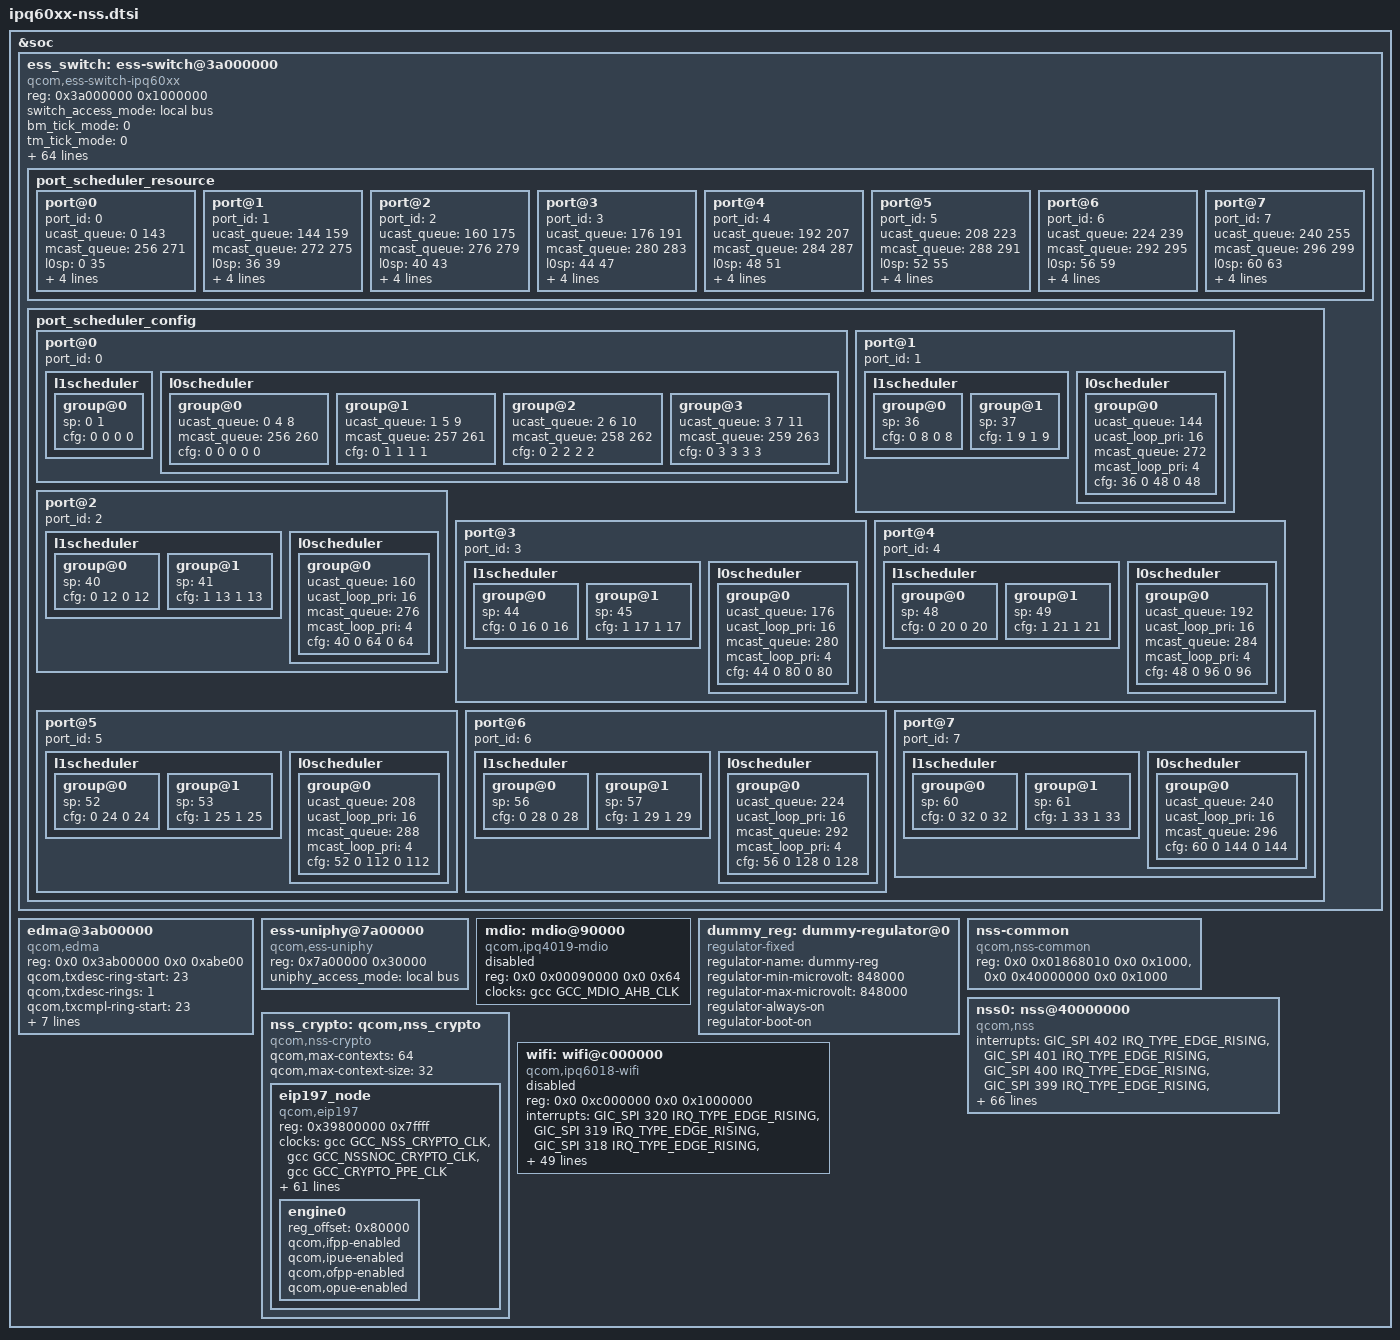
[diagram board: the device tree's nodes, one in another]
// SPDX-License-Identifier: GPL-2.0-only

&soc {
	ess_switch: ess-switch@3a000000 {
		compatible = "qcom,ess-switch-ipq60xx";
		reg = <0x3a000000 0x1000000>;
		switch_access_mode = "local bus";
    		bm_tick_mode = <0>; /* bm tick mode */
    		tm_tick_mode = <0>; /* tm tick mode */
		mdio-bus = <&mdio>;
		clocks = <&gcc GCC_CMN_12GPLL_AHB_CLK>,
			<&gcc GCC_CMN_12GPLL_SYS_CLK>,
			<&gcc GCC_UNIPHY0_AHB_CLK>,
			<&gcc GCC_UNIPHY0_SYS_CLK>,
			<&gcc GCC_UNIPHY1_AHB_CLK>,
			<&gcc GCC_UNIPHY1_SYS_CLK>,
			<&gcc GCC_PORT1_MAC_CLK>,
			<&gcc GCC_PORT2_MAC_CLK>,
			<&gcc GCC_PORT3_MAC_CLK>,
			<&gcc GCC_PORT4_MAC_CLK>,
			<&gcc GCC_PORT5_MAC_CLK>,
			<&gcc GCC_NSS_PPE_CLK>,
			<&gcc GCC_NSS_PPE_CFG_CLK>,
			<&gcc GCC_NSSNOC_PPE_CLK>,
			<&gcc GCC_NSSNOC_PPE_CFG_CLK>,
			<&gcc GCC_NSS_EDMA_CLK>,
			<&gcc GCC_NSS_EDMA_CFG_CLK>,
			<&gcc GCC_NSS_PPE_IPE_CLK>,
			<&gcc GCC_MDIO_AHB_CLK>,
			<&gcc GCC_NSS_NOC_CLK>,
			<&gcc GCC_NSSNOC_SNOC_CLK>,
			<&gcc GCC_NSS_CRYPTO_CLK>,
			<&gcc GCC_NSS_PTP_REF_CLK>,
			<&gcc GCC_NSS_PORT1_RX_CLK>,
			<&gcc GCC_NSS_PORT1_TX_CLK>,
			<&gcc GCC_NSS_PORT2_RX_CLK>,
			<&gcc GCC_NSS_PORT2_TX_CLK>,
			<&gcc GCC_NSS_PORT3_RX_CLK>,
			<&gcc GCC_NSS_PORT3_TX_CLK>,
			<&gcc GCC_NSS_PORT4_RX_CLK>,
			<&gcc GCC_NSS_PORT4_TX_CLK>,
			<&gcc GCC_NSS_PORT5_RX_CLK>,
			<&gcc GCC_NSS_PORT5_TX_CLK>,
			<&gcc GCC_UNIPHY0_PORT1_RX_CLK>,
			<&gcc GCC_UNIPHY0_PORT1_TX_CLK>,
			<&gcc GCC_UNIPHY0_PORT2_RX_CLK>,
			<&gcc GCC_UNIPHY0_PORT2_TX_CLK>,
			<&gcc GCC_UNIPHY0_PORT3_RX_CLK>,
			<&gcc GCC_UNIPHY0_PORT3_TX_CLK>,
			<&gcc GCC_UNIPHY0_PORT4_RX_CLK>,
			<&gcc GCC_UNIPHY0_PORT4_TX_CLK>,
			<&gcc GCC_UNIPHY0_PORT5_RX_CLK>,
			<&gcc GCC_UNIPHY0_PORT5_TX_CLK>,
			<&gcc GCC_UNIPHY1_PORT5_RX_CLK>,
			<&gcc GCC_UNIPHY1_PORT5_TX_CLK>,
			<&gcc NSS_PORT5_RX_CLK_SRC>,
			<&gcc NSS_PORT5_TX_CLK_SRC>,
			<&gcc GCC_SNOC_NSSNOC_CLK>;
			clock-names = "cmn_ahb_clk", "cmn_sys_clk",
					"uniphy0_ahb_clk", "uniphy0_sys_clk",
					"uniphy1_ahb_clk", "uniphy1_sys_clk",
					"port1_mac_clk", "port2_mac_clk",
					"port3_mac_clk", "port4_mac_clk",
					"port5_mac_clk",
					"nss_ppe_clk", "nss_ppe_cfg_clk",
					"nssnoc_ppe_clk", "nssnoc_ppe_cfg_clk",
					"nss_edma_clk", "nss_edma_cfg_clk",
					"nss_ppe_ipe_clk",
					"gcc_mdio_ahb_clk", "gcc_nss_noc_clk",
					"gcc_nssnoc_snoc_clk",
					"gcc_nss_crypto_clk",
					"gcc_nss_ptp_ref_clk",
					"nss_port1_rx_clk", "nss_port1_tx_clk",
					"nss_port2_rx_clk", "nss_port2_tx_clk",
					"nss_port3_rx_clk", "nss_port3_tx_clk",
					"nss_port4_rx_clk", "nss_port4_tx_clk",
					"nss_port5_rx_clk", "nss_port5_tx_clk",
					"uniphy0_port1_rx_clk",
					"uniphy0_port1_tx_clk",
					"uniphy0_port2_rx_clk",
					"uniphy0_port2_tx_clk",
					"uniphy0_port3_rx_clk",
					"uniphy0_port3_tx_clk",
					"uniphy0_port4_rx_clk",
					"uniphy0_port4_tx_clk",
					"uniphy0_port5_rx_clk",
					"uniphy0_port5_tx_clk",
					"uniphy1_port5_rx_clk",
					"uniphy1_port5_tx_clk",
					"nss_port5_rx_clk_src",
					"nss_port5_tx_clk_src",
					"gcc_snoc_nssnoc_clk";
		resets = <&gcc GCC_PPE_FULL_RESET>,
			<&gcc GCC_UNIPHY0_SOFT_RESET>,
			<&gcc GCC_UNIPHY0_XPCS_RESET>,
			<&gcc GCC_UNIPHY1_SOFT_RESET>,
			<&gcc GCC_UNIPHY1_XPCS_RESET>,
			<&gcc GCC_NSSPORT1_RESET>,
			<&gcc GCC_NSSPORT2_RESET>,
			<&gcc GCC_NSSPORT3_RESET>,
			<&gcc GCC_NSSPORT4_RESET>,
			<&gcc GCC_NSSPORT5_RESET>,
			<&gcc GCC_UNIPHY0_PORT1_ARES>,
			<&gcc GCC_UNIPHY0_PORT2_ARES>,
			<&gcc GCC_UNIPHY0_PORT3_ARES>,
			<&gcc GCC_UNIPHY0_PORT4_ARES>,
			<&gcc GCC_UNIPHY0_PORT5_ARES>,
			<&gcc GCC_UNIPHY0_PORT_4_5_RESET>,
			<&gcc GCC_UNIPHY0_PORT_4_RESET>;
		reset-names = "ppe_rst", "uniphy0_soft_rst",
				"uniphy0_xpcs_rst", "uniphy1_soft_rst",
				"uniphy1_xpcs_rst", "nss_port1_rst",
				"nss_port2_rst", "nss_port3_rst",
				"nss_port4_rst", "nss_port5_rst",
				"uniphy0_port1_dis",
				"uniphy0_port2_dis",
				"uniphy0_port3_dis",
				"uniphy0_port4_dis",
				"uniphy0_port5_dis",
				"uniphy0_port_4_5_rst",
				"uniphy0_port_4_rst";
    		port_scheduler_resource {
    			port@0 {
    				port_id = <0>;
    				ucast_queue = <0 143>;
    				mcast_queue = <256 271>;
    				l0sp = <0 35>;
    				l0cdrr = <0 47>;
    				l0edrr = <0 47>;
    				l1cdrr = <0 7>;
    				l1edrr = <0 7>;
    			};
    			port@1 {
    				port_id = <1>;
    				ucast_queue = <144 159>;
    				mcast_queue = <272 275>;
    				l0sp = <36 39>;
    				l0cdrr = <48 63>;
    				l0edrr = <48 63>;
    				l1cdrr = <8 11>;
    				l1edrr = <8 11>;
    			};
    			port@2 {
    				port_id = <2>;
    				ucast_queue = <160 175>;
    				mcast_queue = <276 279>;
    				l0sp = <40 43>;
    				l0cdrr = <64 79>;
    				l0edrr = <64 79>;
    				l1cdrr = <12 15>;
    				l1edrr = <12 15>;
    			};
    			port@3 {
    				port_id = <3>;
    				ucast_queue = <176 191>;
    				mcast_queue = <280 283>;
    				l0sp = <44 47>;
    				l0cdrr = <80 95>;
    				l0edrr = <80 95>;
    				l1cdrr = <16 19>;
    				l1edrr = <16 19>;
    			};
    			port@4 {
    				port_id = <4>;
    				ucast_queue = <192 207>;
    				mcast_queue = <284 287>;
    				l0sp = <48 51>;
    				l0cdrr = <96 111>;
    				l0edrr = <96 111>;
    				l1cdrr = <20 23>;
    				l1edrr = <20 23>;
    			};
    			port@5 {
    				port_id = <5>;
    				ucast_queue = <208 223>;
    				mcast_queue = <288 291>;
    				l0sp = <52 55>;
    				l0cdrr = <112 127>;
    				l0edrr = <112 127>;
    				l1cdrr = <24 27>;
    				l1edrr = <24 27>;
    			};
    			port@6 {
    				port_id = <6>;
    				ucast_queue = <224 239>;
    				mcast_queue = <292 295>;
    				l0sp = <56 59>;
    				l0cdrr = <128 143>;
    				l0edrr = <128 143>;
    				l1cdrr = <28 31>;
    				l1edrr = <28 31>;
    			};
    			port@7 {
    				port_id = <7>;
    				ucast_queue = <240 255>;
    				mcast_queue = <296 299>;
    				l0sp = <60 63>;
    				l0cdrr = <144 159>;
    				l0edrr = <144 159>;
    				l1cdrr = <32 35>;
    				l1edrr = <32 35>;
    			};
    		};
    		port_scheduler_config {
    			port@0 {
    				port_id = <0>;
    				l1scheduler {
    					group@0 {
    						sp = <0 1>; /*L0 SPs*/
    						/*cpri cdrr epri edrr*/
    						cfg = <0 0 0 0>;
    					};
    				};
    				l0scheduler {
    					group@0 {
    						/*unicast queues*/
    						ucast_queue = <0 4 8>;
    						/*multicast queues*/
    						mcast_queue = <256 260>;
    						/*sp cpricdrrepriedrr*/
    						cfg = <0 0 0 0 0>;
    					};
    					group@1 {
    						ucast_queue = <1 5 9>;
    						mcast_queue = <257 261>;
    						cfg = <0 1 1 1 1>;
    					};
    					group@2 {
    						ucast_queue = <2 6 10>;
    						mcast_queue = <258 262>;
    						cfg = <0 2 2 2 2>;
    					};
    					group@3 {
    						ucast_queue = <3 7 11>;
    						mcast_queue = <259 263>;
    						cfg = <0 3 3 3 3>;
    					};
    				};
    			};
    			port@1 {
    				port_id = <1>;
    				l1scheduler {
    					group@0 {
    						sp = <36>;
    						cfg = <0 8 0 8>;
    					};
    					group@1 {
    						sp = <37>;
    						cfg = <1 9 1 9>;
    					};
    				};
    				l0scheduler {
    					group@0 {
    						ucast_queue = <144>;
    						ucast_loop_pri = <16>;
    						mcast_queue = <272>;
    						mcast_loop_pri = <4>;
    						cfg = <36 0 48 0 48>;
    					};
    				};
    			};
    			port@2 {
    				port_id = <2>;
    				l1scheduler {
    					group@0 {
    						sp = <40>;
    						cfg = <0 12 0 12>;
    					};
    					group@1 {
    						sp = <41>;
    						cfg = <1 13 1 13>;
    					};
    				};
    				l0scheduler {
    					group@0 {
    						ucast_queue = <160>;
    						ucast_loop_pri = <16>;
    						mcast_queue = <276>;
    						mcast_loop_pri = <4>;
    						cfg = <40 0 64 0 64>;
    					};
    				};
    			};
    			port@3 {
    				port_id = <3>;
    				l1scheduler {
    					group@0 {
    						sp = <44>;
    						cfg = <0 16 0 16>;
    					};
    					group@1 {
    						sp = <45>;
    						cfg = <1 17 1 17>;
    					};
    				};
    				l0scheduler {
    					group@0 {
    						ucast_queue = <176>;
    						ucast_loop_pri = <16>;
    						mcast_queue = <280>;
    						mcast_loop_pri = <4>;
    						cfg = <44 0 80 0 80>;
    					};
    				};
    			};
    			port@4 {
    				port_id = <4>;
    				l1scheduler {
    					group@0 {
    						sp = <48>;
    						cfg = <0 20 0 20>;
    					};
    					group@1 {
    						sp = <49>;
    						cfg = <1 21 1 21>;
    					};
    				};
    				l0scheduler {
    					group@0 {
    						ucast_queue = <192>;
    						ucast_loop_pri = <16>;
    						mcast_queue = <284>;
    						mcast_loop_pri = <4>;
    						cfg = <48 0 96 0 96>;
    					};
    				};
    			};
    			port@5 {
    				port_id = <5>;
    				l1scheduler {
    					group@0 {
    						sp = <52>;
    						cfg = <0 24 0 24>;
    					};
    					group@1 {
    						sp = <53>;
    						cfg = <1 25 1 25>;
    					};
    				};
    				l0scheduler {
    					group@0 {
    						ucast_queue = <208>;
    						ucast_loop_pri = <16>;
    						mcast_queue = <288>;
    						mcast_loop_pri = <4>;
    						cfg = <52 0 112 0 112>;
    					};
    				};
    			};
    			port@6 {
    				port_id = <6>;
    				l1scheduler {
    					group@0 {
    						sp = <56>;
    						cfg = <0 28 0 28>;
    					};
    					group@1 {
    						sp = <57>;
    						cfg = <1 29 1 29>;
    					};
    				};
    				l0scheduler {
    					group@0 {
    						ucast_queue = <224>;
    						ucast_loop_pri = <16>;
    						mcast_queue = <292>;
    						mcast_loop_pri = <4>;
    						cfg = <56 0 128 0 128>;
    					};
    				};
    			};
    			port@7 {
    				port_id = <7>;
    				l1scheduler {
    					group@0 {
    						sp = <60>;
    						cfg = <0 32 0 32>;
    					};
    					group@1 {
    						sp = <61>;
    						cfg = <1 33 1 33>;
    					};
    				};
    				l0scheduler {
    					group@0 {
    						ucast_queue = <240>;
    						ucast_loop_pri = <16>;
    						mcast_queue = <296>;
    						cfg = <60 0 144 0 144>;
    					};
    				};
    			};
    		};
	};

	edma@3ab00000 {
		compatible = "qcom,edma";
		reg = <0x0 0x3ab00000 0x0 0xabe00>;
		reg-names = "edma-reg-base";
		qcom,txdesc-ring-start = <23>;
		qcom,txdesc-rings = <1>;
		qcom,txcmpl-ring-start = <23>;
		qcom,txcmpl-rings = <1>;
		qcom,rxfill-ring-start = <7>;
		qcom,rxfill-rings = <1>;
		qcom,rxdesc-ring-start = <15>;
		qcom,rxdesc-rings = <1>;
		interrupts = <0 378 4>,
			     <0 354 4>,
			     <0 346 4>,
			     <0 379 4>;
		resets = <&gcc GCC_EDMA_HW_RESET>;
		reset-names = "edma_rst";
	};

	ess-uniphy@7a00000 {
		compatible = "qcom,ess-uniphy";
		reg = <0x7a00000 0x30000>;
		uniphy_access_mode = "local bus";
	};

	mdio: mdio@90000 {
		compatible = "qcom,ipq4019-mdio";
		reg = <0x0 0x00090000 0x0 0x64>;
		#address-cells = <1>;
		#size-cells = <0>;

		clocks = <&gcc GCC_MDIO_AHB_CLK>;
		clock-names = "mdio_ahb";

		status = "disabled";
         };

	dummy_reg: dummy-regulator@0 {
		compatible = "regulator-fixed";
		regulator-name = "dummy-reg";
		regulator-min-microvolt = <848000>;
		regulator-max-microvolt = <848000>;
		regulator-always-on;
		regulator-boot-on;
	};

	nss-common {
		compatible = "qcom,nss-common";
		reg = <0x0 0x01868010 0x0 0x1000>, <0x0 0x40000000 0x0 0x1000>;
		reg-names = "nss-misc-reset", "nss-misc-reset-flag";
	};

	nss0: nss@40000000 {
		compatible = "qcom,nss";
		interrupts = <GIC_SPI 402 IRQ_TYPE_EDGE_RISING>,
				 <GIC_SPI 401 IRQ_TYPE_EDGE_RISING>,
				 <GIC_SPI 400 IRQ_TYPE_EDGE_RISING>,
			     <GIC_SPI 399 IRQ_TYPE_EDGE_RISING>, 
				 <GIC_SPI 398 IRQ_TYPE_EDGE_RISING>,
				 <GIC_SPI 397 IRQ_TYPE_EDGE_RISING>,
			     <GIC_SPI 396 IRQ_TYPE_EDGE_RISING>,
				 <GIC_SPI 395 IRQ_TYPE_EDGE_RISING>,
				 <GIC_SPI 394 IRQ_TYPE_EDGE_RISING>,
			     <GIC_SPI 393 IRQ_TYPE_EDGE_RISING>;
		reg = <0x0 0x39000000 0x0 0x1000>, <0x0 0x0b111000 0x0 0x1000>;
		reg-names = "nphys", "qgic-phys";
		clocks = <&gcc GCC_NSS_NOC_CLK>,
			 <&gcc GCC_NSS_PTP_REF_CLK>,
			 <&gcc GCC_NSS_CSR_CLK>, <&gcc GCC_NSS_CFG_CLK>,
			 <&gcc GCC_NSSNOC_QOSGEN_REF_CLK>,
			 <&gcc GCC_NSSNOC_SNOC_CLK>,
			 <&gcc GCC_NSSNOC_TIMEOUT_REF_CLK>,
			 <&gcc GCC_MEM_NOC_UBI32_CLK>,
			 <&gcc GCC_NSS_CE_AXI_CLK>,
			 <&gcc GCC_NSS_CE_APB_CLK>,
			 <&gcc GCC_NSSNOC_CE_AXI_CLK>,
			 <&gcc GCC_NSSNOC_CE_APB_CLK>,
			 <&gcc GCC_NSSNOC_UBI0_AHB_CLK>,
			 <&gcc GCC_UBI0_CORE_CLK>,
			 <&gcc GCC_UBI0_AHB_CLK>,
			 <&gcc GCC_UBI0_AXI_CLK>,
			 <&gcc GCC_UBI0_NC_AXI_CLK>,
			 <&gcc GCC_UBI0_UTCM_CLK>,
			 <&gcc GCC_SNOC_NSSNOC_CLK>;
		clock-names = "nss-noc-clk", "nss-ptp-ref-clk",
			      "nss-csr-clk", "nss-cfg-clk",
			      "nss-nssnoc-qosgen-ref-clk",
			      "nss-nssnoc-snoc-clk",
			      "nss-nssnoc-timeout-ref-clk",
			      "nss-mem-noc-ubi32-clk",
			      "nss-ce-axi-clk", "nss-ce-apb-clk",
			      "nss-nssnoc-ce-axi-clk",
			      "nss-nssnoc-ce-apb-clk",
			      "nss-nssnoc-ahb-clk",
			      "nss-core-clk", "nss-ahb-clk",
			      "nss-axi-clk", "nss-nc-axi-clk",
			      "nss-utcm-clk", "nss-snoc-nssnoc-clk";
		qcom,id = <0>;
		qcom,num-queue = <4>;
		qcom,num-irq = <10>;
		qcom,num-pri = <4>;
		qcom,load-addr = <0x40000000>;
		qcom,low-frequency = <187200000>;
		qcom,mid-frequency = <748800000>;
		qcom,max-frequency = <1497600000>;
		npu-supply = <&dummy_reg>;
		mx-supply = <&dummy_reg>;
		qcom,bridge-enabled;
		qcom,ipv4-enabled;
		qcom,ipv4-reasm-enabled;
		qcom,ipv6-enabled;
		qcom,ipv6-reasm-enabled;
		qcom,wlanredirect-enabled;
		qcom,tun6rd-enabled;
		qcom,l2tpv2-enabled;
		qcom,gre-enabled;
		qcom,gre-redir-enabled;
		qcom,gre-redir-mark-enabled;
		qcom,map-t-enabled;
		qcom,portid-enabled;
		qcom,ppe-enabled;
		qcom,pppoe-enabled;
		qcom,pptp-enabled;
		qcom,tunipip6-enabled;
		qcom,shaping-enabled;
		qcom,wlan-dataplane-offload-enabled;
		qcom,vlan-enabled;
		qcom,capwap-enabled;
		qcom,dtls-enabled;
		qcom,tls-enabled;
		qcom,crypto-enabled;
		qcom,ipsec-enabled;
		qcom,qvpn-enabled;
		qcom,pvxlan-enabled;
		qcom,clmap-enabled;
		qcom,vxlan-enabled;
		qcom,match-enabled;
		qcom,mirror-enabled;
	};

	nss_crypto: qcom,nss_crypto {
		compatible = "qcom,nss-crypto";
		#address-cells = <1>;
		#size-cells = <1>;
		qcom,max-contexts = <64>;
		qcom,max-context-size = <32>;
		ranges;

		eip197_node {
			compatible = "qcom,eip197";
			reg-names = "crypto_pbase";
			reg = <0x39800000 0x7ffff>;
			clocks = <&gcc GCC_NSS_CRYPTO_CLK>,
				<&gcc GCC_NSSNOC_CRYPTO_CLK>,
				<&gcc GCC_CRYPTO_PPE_CLK>;
			clock-names = "crypto_clk", "crypto_nocclk",
					"crypto_ppeclk";
			clock-frequency = /bits/ 64 <300000000 300000000 300000000>;
			qcom,dma-mask = <0xff>;
			qcom,transform-enabled;
			qcom,aes128-cbc;
			qcom,aes192-cbc;
			qcom,aes256-cbc;
			qcom,aes128-ctr;
			qcom,aes192-ctr;
			qcom,aes256-ctr;
			qcom,aes128-ecb;
			qcom,aes192-ecb;
			qcom,aes256-ecb;
			qcom,3des-cbc;
			qcom,md5-hash;
			qcom,sha160-hash;
			qcom,sha224-hash;
			qcom,sha256-hash;
			qcom,sha384-hash;
			qcom,sha512-hash;
			qcom,md5-hmac;
			qcom,sha160-hmac;
			qcom,sha224-hmac;
			qcom,sha256-hmac;
			qcom,sha384-hmac;
			qcom,sha512-hmac;
			qcom,aes128-gcm-gmac;
			qcom,aes192-gcm-gmac;
			qcom,aes256-gcm-gmac;
			qcom,aes128-cbc-md5-hmac;
			qcom,aes128-cbc-sha160-hmac;
			qcom,aes192-cbc-md5-hmac;
			qcom,aes192-cbc-sha160-hmac;
			qcom,aes256-cbc-md5-hmac;
			qcom,aes256-cbc-sha160-hmac;
			qcom,aes128-ctr-sha160-hmac;
			qcom,aes192-ctr-sha160-hmac;
			qcom,aes256-ctr-sha160-hmac;
			qcom,aes128-ctr-md5-hmac;
			qcom,aes192-ctr-md5-hmac;
			qcom,aes256-ctr-md5-hmac;
			qcom,3des-cbc-md5-hmac;
			qcom,3des-cbc-sha160-hmac;
			qcom,aes128-cbc-sha256-hmac;
			qcom,aes192-cbc-sha256-hmac;
			qcom,aes256-cbc-sha256-hmac;
			qcom,aes128-ctr-sha256-hmac;
			qcom,aes192-ctr-sha256-hmac;
			qcom,aes256-ctr-sha256-hmac;
			qcom,3des-cbc-sha256-hmac;
			qcom,aes128-cbc-sha384-hmac;
			qcom,aes192-cbc-sha384-hmac;
			qcom,aes256-cbc-sha384-hmac;
			qcom,aes128-ctr-sha384-hmac;
			qcom,aes192-ctr-sha384-hmac;
			qcom,aes256-ctr-sha384-hmac;
			qcom,aes128-cbc-sha512-hmac;
			qcom,aes192-cbc-sha512-hmac;
			qcom,aes256-cbc-sha512-hmac;
			qcom,aes128-ctr-sha512-hmac;
			qcom,aes192-ctr-sha512-hmac;
			qcom,aes256-ctr-sha512-hmac;

			engine0 {
				reg_offset = <0x80000>;
				qcom,ifpp-enabled;
				qcom,ipue-enabled;
				qcom,ofpp-enabled;
				qcom,opue-enabled;
			};
		};
	};

	wifi: wifi@c000000 {
		compatible = "qcom,ipq6018-wifi";
		reg = <0x0 0xc000000 0x0 0x1000000>;
		interrupts =    <GIC_SPI 320 IRQ_TYPE_EDGE_RISING>,
						<GIC_SPI 319 IRQ_TYPE_EDGE_RISING>,
						<GIC_SPI 318 IRQ_TYPE_EDGE_RISING>,
						<GIC_SPI 316 IRQ_TYPE_EDGE_RISING>,
						<GIC_SPI 315 IRQ_TYPE_EDGE_RISING>,
						<GIC_SPI 314 IRQ_TYPE_EDGE_RISING>,
						<GIC_SPI 311 IRQ_TYPE_EDGE_RISING>,
						<GIC_SPI 310 IRQ_TYPE_EDGE_RISING>,
						<GIC_SPI 411 IRQ_TYPE_EDGE_RISING>,
						<GIC_SPI 410 IRQ_TYPE_EDGE_RISING>,
						<GIC_SPI 40  IRQ_TYPE_EDGE_RISING>,
						<GIC_SPI 39  IRQ_TYPE_EDGE_RISING>,
						<GIC_SPI 302 IRQ_TYPE_EDGE_RISING>,
						<GIC_SPI 301 IRQ_TYPE_EDGE_RISING>,
						<GIC_SPI 37  IRQ_TYPE_EDGE_RISING>,
						<GIC_SPI 36  IRQ_TYPE_EDGE_RISING>,
						<GIC_SPI 296 IRQ_TYPE_EDGE_RISING>,
						<GIC_SPI 295 IRQ_TYPE_EDGE_RISING>,
						<GIC_SPI 294 IRQ_TYPE_EDGE_RISING>,
						<GIC_SPI 293 IRQ_TYPE_EDGE_RISING>,
						<GIC_SPI 292 IRQ_TYPE_EDGE_RISING>,
						<GIC_SPI 291 IRQ_TYPE_EDGE_RISING>,
						<GIC_SPI 290 IRQ_TYPE_EDGE_RISING>,
						<GIC_SPI 289 IRQ_TYPE_EDGE_RISING>,
						<GIC_SPI 288 IRQ_TYPE_EDGE_RISING>,
						<GIC_SPI 239 IRQ_TYPE_EDGE_RISING>,
						<GIC_SPI 236 IRQ_TYPE_EDGE_RISING>,
						<GIC_SPI 235 IRQ_TYPE_EDGE_RISING>,
						<GIC_SPI 234 IRQ_TYPE_EDGE_RISING>,
						<GIC_SPI 233 IRQ_TYPE_EDGE_RISING>,
						<GIC_SPI 232 IRQ_TYPE_EDGE_RISING>,
						<GIC_SPI 231 IRQ_TYPE_EDGE_RISING>,
						<GIC_SPI 230 IRQ_TYPE_EDGE_RISING>,
						<GIC_SPI 229 IRQ_TYPE_EDGE_RISING>,
						<GIC_SPI 228 IRQ_TYPE_EDGE_RISING>,
						<GIC_SPI 224 IRQ_TYPE_EDGE_RISING>,
						<GIC_SPI 223 IRQ_TYPE_EDGE_RISING>,
						<GIC_SPI 203 IRQ_TYPE_EDGE_RISING>,
						<GIC_SPI 183 IRQ_TYPE_EDGE_RISING>,
						<GIC_SPI 180 IRQ_TYPE_EDGE_RISING>,
						<GIC_SPI 179 IRQ_TYPE_EDGE_RISING>,
						<GIC_SPI 178 IRQ_TYPE_EDGE_RISING>,
						<GIC_SPI 177 IRQ_TYPE_EDGE_RISING>,
						<GIC_SPI 176 IRQ_TYPE_EDGE_RISING>,
						<GIC_SPI 163 IRQ_TYPE_EDGE_RISING>,
						<GIC_SPI 162 IRQ_TYPE_EDGE_RISING>,
						<GIC_SPI 160 IRQ_TYPE_EDGE_RISING>,
						<GIC_SPI 159 IRQ_TYPE_EDGE_RISING>,
						<GIC_SPI 158 IRQ_TYPE_EDGE_RISING>,
						<GIC_SPI 157 IRQ_TYPE_EDGE_RISING>,
						<GIC_SPI 156 IRQ_TYPE_EDGE_RISING>;

		interrupt-names =   "misc-pulse1",
							"misc-latch",
							"sw-exception",
							"ce0",
							"ce1",
							"ce2",
							"ce3",
							"ce4",
							"ce5",
							"ce6",
							"ce7",
							"ce8",
							"ce9",
							"ce10",
							"ce11",
							"host2wbm-desc-feed",
							"host2reo-re-injection",
							"host2reo-command",
							"host2rxdma-monitor-ring3",
							"host2rxdma-monitor-ring2",
							"host2rxdma-monitor-ring1",
							"reo2ost-exception",
							"wbm2host-rx-release",
							"reo2host-status",
							"reo2host-destination-ring4",
							"reo2host-destination-ring3",
							"reo2host-destination-ring2",
							"reo2host-destination-ring1",
							"rxdma2host-monitor-destination-mac3",
							"rxdma2host-monitor-destination-mac2",
							"rxdma2host-monitor-destination-mac1",
							"ppdu-end-interrupts-mac3",
							"ppdu-end-interrupts-mac2",
							"ppdu-end-interrupts-mac1",
							"rxdma2host-monitor-status-ring-mac3",
							"rxdma2host-monitor-status-ring-mac2",
							"rxdma2host-monitor-status-ring-mac1",
							"host2rxdma-host-buf-ring-mac3",
							"host2rxdma-host-buf-ring-mac2",
							"host2rxdma-host-buf-ring-mac1",
							"rxdma2host-destination-ring-mac3",
							"rxdma2host-destination-ring-mac2",
							"rxdma2host-destination-ring-mac1",
							"host2tcl-input-ring4",
							"host2tcl-input-ring3",
							"host2tcl-input-ring2",
							"host2tcl-input-ring1",
							"wbm2host-tx-completions-ring3",
							"wbm2host-tx-completions-ring2",
							"wbm2host-tx-completions-ring1",
							"tcl2host-status-ring";
		qcom,rproc = <&q6v5_wcss>;
		status = "disabled";
	};
};
